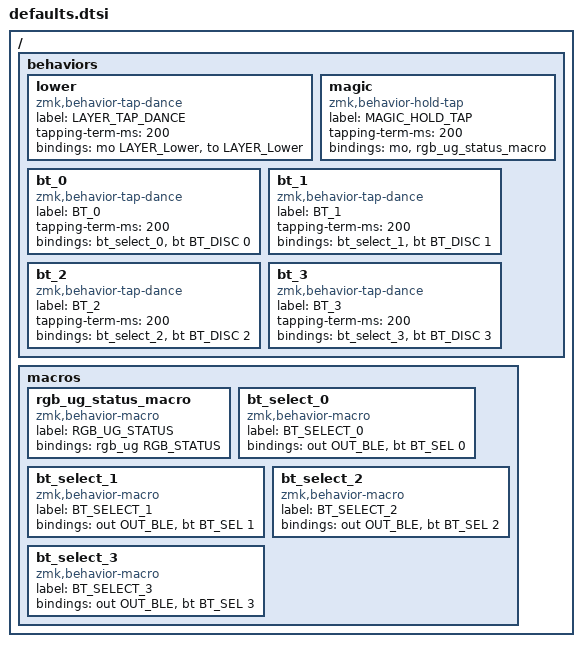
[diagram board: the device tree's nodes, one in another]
/ {
  behaviors {
    lower: lower {
      compatible = "zmk,behavior-tap-dance";
      label = "LAYER_TAP_DANCE";
      #binding-cells = <0>;
      tapping-term-ms = <200>;
      bindings = <&mo LAYER_Lower>, <&to LAYER_Lower>;
    };
  };
};

/ {
  macros {
    rgb_ug_status_macro: rgb_ug_status_macro {
      label = "RGB_UG_STATUS";
      compatible = "zmk,behavior-macro";
      #binding-cells = <0>;
      bindings = <&rgb_ug RGB_STATUS>;
    };
  };
};

/ {
  behaviors {
    magic: magic {
      compatible = "zmk,behavior-hold-tap";
      label = "MAGIC_HOLD_TAP";
      #binding-cells = <2>;
      tapping-term-ms = <200>;
      bindings = <&mo>, <&rgb_ug_status_macro>;
    };
  };
};

// Bluetooth behaviors
/ {
  behaviors {
    bt_0: bt_0 {
      compatible = "zmk,behavior-tap-dance";
      label = "BT_0";
      #binding-cells = <0>;
      tapping-term-ms = <200>;
      bindings = <&bt_select_0>, <&bt BT_DISC 0>;
    };
    bt_1: bt_1 {
      compatible = "zmk,behavior-tap-dance";
      label = "BT_1";
      #binding-cells = <0>;
      tapping-term-ms = <200>;
      bindings = <&bt_select_1>, <&bt BT_DISC 1>;
    };
    bt_2: bt_2 {
      compatible = "zmk,behavior-tap-dance";
      label = "BT_2";
      #binding-cells = <0>;
      tapping-term-ms = <200>;
      bindings = <&bt_select_2>, <&bt BT_DISC 2>;
    };
    bt_3: bt_3 {
      compatible = "zmk,behavior-tap-dance";
      label = "BT_3";
      #binding-cells = <0>;
      tapping-term-ms = <200>;
      bindings = <&bt_select_3>, <&bt BT_DISC 3>;
    };
  };
  macros {
    bt_select_0: bt_select_0 {
      label = "BT_SELECT_0";
      compatible = "zmk,behavior-macro";
      #binding-cells = <0>;
      bindings = <&out OUT_BLE>, <&bt BT_SEL 0>;
    };
    bt_select_1: bt_select_1 {
      label = "BT_SELECT_1";
      compatible = "zmk,behavior-macro";
      #binding-cells = <0>;
      bindings = <&out OUT_BLE>, <&bt BT_SEL 1>;
    };
    bt_select_2: bt_select_2 {
      label = "BT_SELECT_2";
      compatible = "zmk,behavior-macro";
      #binding-cells = <0>;
      bindings = <&out OUT_BLE>, <&bt BT_SEL 2>;
    };
    bt_select_3: bt_select_3 {
      label = "BT_SELECT_3";
      compatible = "zmk,behavior-macro";
      #binding-cells = <0>;
      bindings = <&out OUT_BLE>, <&bt BT_SEL 3>;
    };
  };
};
